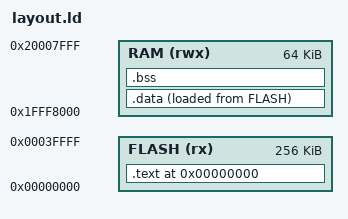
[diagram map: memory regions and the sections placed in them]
/*
Copyright (c) 2015 Michael Daffin

Permission is hereby granted, free of charge, to any person obtaining a copy
of this software and associated documentation files (the "Software"), to deal
in the Software without restriction, including without limitation the rights
to use, copy, modify, merge, publish, distribute, sublicense, and/or sell
copies of the Software, and to permit persons to whom the Software is
furnished to do so, subject to the following conditions:

The above copyright notice and this permission notice shall be included in
all copies or substantial portions of the Software.

THE SOFTWARE IS PROVIDED "AS IS", WITHOUT WARRANTY OF ANY KIND, EXPRESS OR
IMPLIED, INCLUDING BUT NOT LIMITED TO THE WARRANTIES OF MERCHANTABILITY,
FITNESS FOR A PARTICULAR PURPOSE AND NONINFRINGEMENT.  IN NO EVENT SHALL THE
AUTHORS OR COPYRIGHT HOLDERS BE LIABLE FOR ANY CLAIM, DAMAGES OR OTHER
LIABILITY, WHETHER IN AN ACTION OF CONTRACT, TORT OR OTHERWISE, ARISING FROM,
OUT OF OR IN CONNECTION WITH THE SOFTWARE OR THE USE OR OTHER DEALINGS IN
THE SOFTWARE.
*/

/*
A very basic linker script for the teensy 3.1. Page references refer to the
programmers manual for the MK20DX256VLH7 which can be found at:
https://www.pjrc.com/teensy/K20P64M72SF1RM.pdf
*/

_sflashdata = LOADADDR(.data);

MEMORY {
    FLASH (rx) : ORIGIN = 0x00000000, LENGTH = 256K
    RAM  (rwx) : ORIGIN = 0x1FFF8000, LENGTH = 64K /* page 90 */
}

SECTIONS {
    . = 0x00000000;
    .text : {
        KEEP(*(.vectors)) /* vectors must be placed first - page 63*/
        . = 0x400;
        KEEP(*(.flashconfig*)) /* flash configuration starts at 0x400 - page 569 */
        *(.startup*)
        *(.text*)
        *(.rodata*)
        . = ALIGN(4);
    } > FLASH

    .data : {
        . = ALIGN(4);
        _sdata = .;
        *(.fastrun*)
        *(.data*)
        . = ALIGN(4);
        _edata = .;
    } > RAM AT > FLASH

    .bss : {
        . = ALIGN(4);
        _sbss = .;
        *(.bss*)
        *(COMMON)
        . = ALIGN(4);
        _ebss = .;
    } > RAM

    _estack = ORIGIN(RAM) + LENGTH(RAM); /* stack pointer start */
}
